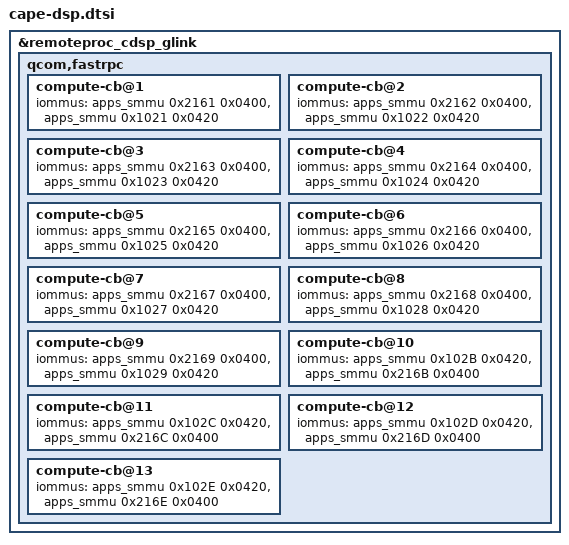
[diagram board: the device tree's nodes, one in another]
// SPDX-License-Identifier: BSD-3-Clause
// SPDX-FileCopyrightText: 2026 The PenguinOS Project

#include "waipio-dsp.dtsi"

&remoteproc_cdsp_glink {
	qcom,fastrpc {
		compute-cb@1 {
			iommus = <&apps_smmu 0x2161 0x0400>,
				 <&apps_smmu 0x1021 0x0420>;
		};

		compute-cb@2 {
			iommus = <&apps_smmu 0x2162 0x0400>,
				 <&apps_smmu 0x1022 0x0420>;
		};

		compute-cb@3 {
			iommus = <&apps_smmu 0x2163 0x0400>,
				 <&apps_smmu 0x1023 0x0420>;
		};

		compute-cb@4 {
			iommus = <&apps_smmu 0x2164 0x0400>,
				 <&apps_smmu 0x1024 0x0420>;
		};

		compute-cb@5 {
			iommus = <&apps_smmu 0x2165 0x0400>,
				 <&apps_smmu 0x1025 0x0420>;
		};

		compute-cb@6 {
			iommus = <&apps_smmu 0x2166 0x0400>,
				 <&apps_smmu 0x1026 0x0420>;
		};

		compute-cb@7 {
			iommus = <&apps_smmu 0x2167 0x0400>,
				 <&apps_smmu 0x1027 0x0420>;
		};

		compute-cb@8 {
			iommus = <&apps_smmu 0x2168 0x0400>,
				 <&apps_smmu 0x1028 0x0420>;
		};

		compute-cb@9 {
			iommus = <&apps_smmu 0x2169 0x0400>,
				 <&apps_smmu 0x1029 0x0420>;
		};

		compute-cb@10 {
			iommus = <&apps_smmu 0x102B 0x0420>,
				 <&apps_smmu 0x216B 0x0400>;
		};

		compute-cb@11 {
			iommus = <&apps_smmu 0x102C 0x0420>,
				 <&apps_smmu 0x216C 0x0400>;
		};

		compute-cb@12 {
			iommus = <&apps_smmu 0x102D 0x0420>,
				 <&apps_smmu 0x216D 0x0400>;
		};

		compute-cb@13 {
			iommus = <&apps_smmu 0x102E 0x0420>,
				 <&apps_smmu 0x216E 0x0400>;
		};
	};
};
